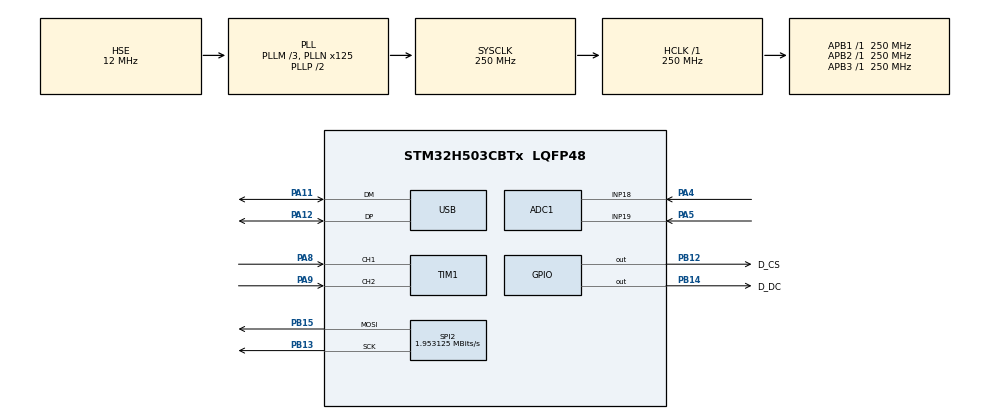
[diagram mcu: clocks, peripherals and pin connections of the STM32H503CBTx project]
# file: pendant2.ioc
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ADC1.Channel-0\#ChannelRegularConversion=ADC_CHANNEL_18
ADC1.Channel-1\#ChannelRegularConversion=ADC_CHANNEL_19
ADC1.ContinuousConvMode=ENABLE
ADC1.DMAContinuousRequests=ENABLE
ADC1.EOCSelection=ADC_EOC_SEQ_CONV
ADC1.MonitoredBy-0\#ChannelRegularConversion=__NULL
ADC1.MonitoredBy-1\#ChannelRegularConversion=__NULL
ADC1.NbrOfConversion=2
ADC1.NbrOfConversionFlag=1
ADC1.OffsetNumber-0\#ChannelRegularConversion=ADC_OFFSET_NONE
ADC1.OffsetNumber-1\#ChannelRegularConversion=ADC_OFFSET_NONE
ADC1.Rank-0\#ChannelRegularConversion=1
ADC1.Rank-1\#ChannelRegularConversion=2
ADC1.SamplingMode=ADC_SAMPLING_MODE_NORMAL
ADC1.SamplingTime-0\#ChannelRegularConversion=ADC_SAMPLETIME_47CYCLES_5
ADC1.SamplingTime-1\#ChannelRegularConversion=ADC_SAMPLETIME_47CYCLES_5
ADC1.master=1
BOOTPATH.BootPathName=LEGACY
BOOTPATH.UserSelectedBootPath=LEGACY
GPDMA1.CIRCULARMODE_GPDMACH2=ENABLE
GPDMA1.DESTDATAWIDTH_GPDMACH2=DMA_DEST_DATAWIDTH_WORD
GPDMA1.DESTINC_GPDMACH2=DMA_DINC_INCREMENTED
GPDMA1.DIRECTION_GPDMACH0=DMA_MEMORY_TO_PERIPH
GPDMA1.IPHANDLE_GPDMACH0-SIMPLEREQUEST_GPDMACH0=__NULL
GPDMA1.IPHANDLE_GPDMACH2-SIMPLEREQUEST_GPDMACH2=__NULL
GPDMA1.REQUEST_GPDMACH0=GPDMA1_REQUEST_SPI2_TX
GPDMA1.REQUEST_GPDMACH2=GPDMA1_REQUEST_ADC1
GPDMA1.SRCBURSTLENGTH_GPDMACH0=64
GPDMA1.SRCDATAWIDTH_GPDMACH2=DMA_SRC_DATAWIDTH_WORD
GPDMA1.SRCINC_GPDMACH0=DMA_SINC_INCREMENTED
Mcu.Family=STM32H5
Mcu.Name=STM32H503CBTx
Mcu.Package=LQFP48
NVIC.GPDMA1_Channel0_IRQn=true\:0\:0\:false\:false\:true\:false\:true\:true
NVIC.GPDMA1_Channel2_IRQn=true\:0\:0\:false\:false\:true\:false\:true\:true
NVIC.PriorityGroup=NVIC_PRIORITYGROUP_4
NVIC.SPI2_IRQn=true\:0\:0\:false\:false\:true\:true\:true\:true
NVIC.USB_DRD_FS_IRQn=true\:0\:0\:false\:false\:true\:true\:true\:true
PA11.Mode=Device
PA11.Signal=USB_DM
PA12.Mode=Device
PA12.Signal=USB_DP
PA3.Signal=ADCx_INP15
PA4.Signal=ADCx_INP18
PA5.Signal=ADCx_INP19
PA8.Signal=S_TIM1_CH1
PA9.Signal=S_TIM1_CH2
PB12.GPIO_Label=D_CS
PB12.Signal=GPIO_Output
PB13.Mode=TX_Only_Simplex_Unidirect_Master
PB13.Signal=SPI2_SCK
PB14.GPIO_Label=D_DC
PB14.Signal=GPIO_Output
PB15.Mode=TX_Only_Simplex_Unidirect_Master
PB15.Signal=SPI2_MOSI
PH0-OSC_IN(PH0).Mode=HSE-External-Oscillator
PH0-OSC_IN(PH0).Signal=RCC_OSC_IN
PH1-OSC_OUT(PH1).Mode=HSE-External-Oscillator
PH1-OSC_OUT(PH1).Signal=RCC_OSC_OUT
ProjectManager.HeapSize=0x300
ProjectManager.StackSize=0x500
ProjectManager.TargetToolchain=Makefile
RCC.ADCCLockSelection=RCC_ADCDACCLKSOURCE_CSI
RCC.ADCFreq_Value=4000000
RCC.AHBFreq_Value=250000000
RCC.APB1Freq_Value=250000000
RCC.APB1TimFreq_Value=250000000
RCC.APB2Freq_Value=250000000
RCC.APB2TimFreq_Value=250000000
RCC.APB3Freq_Value=250000000
RCC.CSI_VALUE=4000000
RCC.CortexFreq_Value=250000000
RCC.EPOD_VALUE=12000000
RCC.EnbaleCSS=true
RCC.HCLKFreq_Value=250000000
RCC.HSE_VALUE=12000000
RCC.HSI48_VALUE=48000000
RCC.HSI_VALUE=64000000
RCC.LSE_VALUE=32768
RCC.LSIRC_VALUE=32000
RCC.PLL2FRACN=0
RCC.PLL2Source=RCC_PLL2_SOURCE_HSE
RCC.PLLFRACN=0
RCC.PLLM=3
RCC.PLLN=125
RCC.PLLSourceVirtual=RCC_PLL1_SOURCE_HSE
RCC.SYSCLKFreq_VALUE=250000000
RCC.SYSCLKSource=RCC_SYSCLKSOURCE_PLLCLK
RCC.USBFreq_Value=48000000
RCC.VCOOutputFreq_Value=500000000
SH.ADCx_INP15.0=ADC1_INP15
SH.ADCx_INP18.0=ADC1_INP18,IN18-Single-Ended
SH.ADCx_INP19.0=ADC1_INP19,IN19-Single-Ended
SH.S_TIM1_CH1.0=TIM1_CH1,Encoder_Interface
SH.S_TIM1_CH2.0=TIM1_CH2,Encoder_Interface
SPI2.BaudRatePrescaler=SPI_BAUDRATEPRESCALER_128
SPI2.CLKPolarity=SPI_POLARITY_LOW
SPI2.CalculateBaudRate=1.953125 MBits/s
SPI2.DataSize=SPI_DATASIZE_8BIT
SPI2.Direction=SPI_DIRECTION_2LINES_TXONLY
SPI2.Mode=SPI_MODE_MASTER
SPI2.VirtualType=VM_MASTER
TIM1.EncoderMode=TIM_ENCODERMODE_X1_TI1
USB.VirtualMode=Device_Only
VP_ADC1_TempSens_Input.Mode=IN-TempSens
VP_ADC1_Vref_Input.Mode=IN-Vrefint
VP_BOOTPATH_VS_BOOTPATH.Mode=BP_Activate
VP_CORTEX_M33_NS_VS_Hclk.Mode=Hclk_Mode
VP_CRC_VS_CRC.Mode=CRC_Activate
VP_FLASH_SIG_Activate_FlashIP.Mode=Activate_FlashIP
VP_GPDMA1_VS_GPDMACH0.Mode=SIMPLEREQUEST_GPDMACH0
VP_GPDMA1_VS_GPDMACH2.Mode=SIMPLEREQUEST_GPDMACH2
VP_ICACHE_VS_ICACHE.Mode=DirectMappedCache
VP_MEMORYMAP_VS_MEMORYMAP.Mode=CurAppReg
VP_PWR_VS_DBSignals.Mode=DisableDeadBatterySignals
VP_PWR_VS_LPOM.Mode=PowerOptimisation
VP_PWR_VS_SECSignals.Mode=Security/Privilege
board=custom

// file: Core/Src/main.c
/* USER CODE BEGIN Header */
/**
  ******************************************************************************
  * @file           : main.c
  * @brief          : Main program body
  ******************************************************************************
  * @attention
  *
  * Copyright (c) 2024 STMicroelectronics.
  * All rights reserved.
  *
  * This software is licensed under terms that can be found in the LICENSE file
  * in the root directory of this software component.
  * If no LICENSE file comes with this software, it is provided AS-IS.
  *
  ******************************************************************************
  */
/* USER CODE END Header */
#include "main.h"

/* USER CODE BEGIN Includes */
#include "usbd_core.h"
#include "usbd_device.h"
#include "platform.h"
/* USER CODE END Includes */

/* USER CODE BEGIN PTD */
USBD_HandleTypeDef hUsbDeviceFS = {0};
extern USBD_DescriptorsTypeDef usbd_class_descriptors;
/* USER CODE END PTD */

ADC_HandleTypeDef hadc1;
DMA_NodeTypeDef Node_GPDMA1_Channel2;
DMA_QListTypeDef List_GPDMA1_Channel2;
DMA_HandleTypeDef handle_GPDMA1_Channel2;

CRC_HandleTypeDef hcrc;

SPI_HandleTypeDef hspi2;
DMA_HandleTypeDef handle_GPDMA1_Channel0;

TIM_HandleTypeDef htim1;

PCD_HandleTypeDef hpcd_USB_DRD_FS;

void SystemClock_Config(void);
static void MX_GPIO_Init(void);
static void MX_GPDMA1_Init(void);
static void MX_CRC_Init(void);
static void MX_FLASH_Init(void);
static void MX_ICACHE_Init(void);
static void MX_USB_PCD_Init(void);
static void MX_ADC1_Init(void);
static void MX_SPI2_Init(void);
static void MX_TIM1_Init(void);

int main(void)
{

  /* MCU Configuration--------------------------------------------------------*/

  /* Reset of all peripherals, Initializes the Flash interface and the Systick. */
  HAL_Init();

  /* Configure the system clock */
  SystemClock_Config();

  /* USER CODE BEGIN SysInit */
  usdb_desc_init();
  /* USER CODE END SysInit */

  /* Initialize all configured peripherals */
  MX_GPIO_Init();
  MX_GPDMA1_Init();
  MX_CRC_Init();
  MX_FLASH_Init();
  MX_ICACHE_Init();
  MX_USB_PCD_Init();
  MX_ADC1_Init();
  MX_SPI2_Init();
  MX_TIM1_Init();
  /* USER CODE BEGIN 2 */
  init();
  /* USER CODE END 2 */

  /* Infinite loop */
  /* USER CODE BEGIN WHILE */
  while (1)
  {
    loop();
    /* USER CODE END WHILE */

  }
}

void SystemClock_Config(void)
{
  RCC_OscInitTypeDef RCC_OscInitStruct = {0};
  RCC_ClkInitTypeDef RCC_ClkInitStruct = {0};

  /** Configure the main internal regulator output voltage
  */
  __HAL_PWR_VOLTAGESCALING_CONFIG(PWR_REGULATOR_VOLTAGE_SCALE0);

  while(!__HAL_PWR_GET_FLAG(PWR_FLAG_VOSRDY)) {}

  /** Initializes the RCC Oscillators according to the specified parameters
  * in the RCC_OscInitTypeDef structure.
  */
  RCC_OscInitStruct.OscillatorType = RCC_OSCILLATORTYPE_HSI48|RCC_OSCILLATORTYPE_HSE
                              |RCC_OSCILLATORTYPE_CSI;
  RCC_OscInitStruct.HSEState = RCC_HSE_ON;
  RCC_OscInitStruct.HSI48State = RCC_HSI48_ON;
  RCC_OscInitStruct.CSIState = RCC_CSI_ON;
  RCC_OscInitStruct.CSICalibrationValue = RCC_CSICALIBRATION_DEFAULT;
  RCC_OscInitStruct.PLL.PLLState = RCC_PLL_ON;
  RCC_OscInitStruct.PLL.PLLSource = RCC_PLL1_SOURCE_HSE;
  RCC_OscInitStruct.PLL.PLLM = 3;
  RCC_OscInitStruct.PLL.PLLN = 125;
  RCC_OscInitStruct.PLL.PLLP = 2;
  RCC_OscInitStruct.PLL.PLLQ = 2;
  RCC_OscInitStruct.PLL.PLLR = 2;
  RCC_OscInitStruct.PLL.PLLRGE = RCC_PLL1_VCIRANGE_2;
  RCC_OscInitStruct.PLL.PLLVCOSEL = RCC_PLL1_VCORANGE_WIDE;
  RCC_OscInitStruct.PLL.PLLFRACN = 0;
  if (HAL_RCC_OscConfig(&RCC_OscInitStruct) != HAL_OK)
  {
    Error_Handler();
  }

  /** Initializes the CPU, AHB and APB buses clocks
  */
  RCC_ClkInitStruct.ClockType = RCC_CLOCKTYPE_HCLK|RCC_CLOCKTYPE_SYSCLK
                              |RCC_CLOCKTYPE_PCLK1|RCC_CLOCKTYPE_PCLK2
                              |RCC_CLOCKTYPE_PCLK3;
  RCC_ClkInitStruct.SYSCLKSource = RCC_SYSCLKSOURCE_PLLCLK;
  RCC_ClkInitStruct.AHBCLKDivider = RCC_SYSCLK_DIV1;
  RCC_ClkInitStruct.APB1CLKDivider = RCC_HCLK_DIV1;
  RCC_ClkInitStruct.APB2CLKDivider = RCC_HCLK_DIV1;
  RCC_ClkInitStruct.APB3CLKDivider = RCC_HCLK_DIV1;

  if (HAL_RCC_ClockConfig(&RCC_ClkInitStruct, FLASH_LATENCY_5) != HAL_OK)
  {
    Error_Handler();
  }

  /** Enables the Clock Security System
  */
  HAL_RCC_EnableCSS();

  /** Configure the programming delay
  */
  __HAL_FLASH_SET_PROGRAM_DELAY(FLASH_PROGRAMMING_DELAY_2);
}

static void MX_ADC1_Init(void)
{

  ADC_ChannelConfTypeDef sConfig = {0};

  /** Common config
  */
  hadc1.Instance = ADC1;
  hadc1.Init.ClockPrescaler = ADC_CLOCK_ASYNC_DIV1;
  hadc1.Init.Resolution = ADC_RESOLUTION_12B;
  hadc1.Init.DataAlign = ADC_DATAALIGN_RIGHT;
  hadc1.Init.ScanConvMode = ADC_SCAN_ENABLE;
  hadc1.Init.EOCSelection = ADC_EOC_SEQ_CONV;
  hadc1.Init.LowPowerAutoWait = DISABLE;
  hadc1.Init.ContinuousConvMode = ENABLE;
  hadc1.Init.NbrOfConversion = 2;
  hadc1.Init.DiscontinuousConvMode = DISABLE;
  hadc1.Init.ExternalTrigConv = ADC_SOFTWARE_START;
  hadc1.Init.ExternalTrigConvEdge = ADC_EXTERNALTRIGCONVEDGE_NONE;
  hadc1.Init.DMAContinuousRequests = ENABLE;
  hadc1.Init.SamplingMode = ADC_SAMPLING_MODE_NORMAL;
  hadc1.Init.Overrun = ADC_OVR_DATA_PRESERVED;
  hadc1.Init.OversamplingMode = DISABLE;
  if (HAL_ADC_Init(&hadc1) != HAL_OK)
  {
    Error_Handler();
  }

  /** Configure Regular Channel
  */
  sConfig.Channel = ADC_CHANNEL_18;
  sConfig.Rank = ADC_REGULAR_RANK_1;
  sConfig.SamplingTime = ADC_SAMPLETIME_47CYCLES_5;
  sConfig.SingleDiff = ADC_SINGLE_ENDED;
  sConfig.OffsetNumber = ADC_OFFSET_NONE;
  sConfig.Offset = 0;
  if (HAL_ADC_ConfigChannel(&hadc1, &sConfig) != HAL_OK)
  {
    Error_Handler();
  }

  /** Configure Regular Channel
  */
  sConfig.Channel = ADC_CHANNEL_19;
  sConfig.Rank = ADC_REGULAR_RANK_2;
  if (HAL_ADC_ConfigChannel(&hadc1, &sConfig) != HAL_OK)
  {
    Error_Handler();
  }
  /* USER CODE BEGIN ADC1_Init 2 */
HAL_ADCEx_Calibration_Start(&hadc1, ADC_SINGLE_ENDED);
  /* USER CODE END ADC1_Init 2 */

}

static void MX_CRC_Init(void)
{

  hcrc.Instance = CRC;
  hcrc.Init.DefaultPolynomialUse = DEFAULT_POLYNOMIAL_ENABLE;
  hcrc.Init.DefaultInitValueUse = DEFAULT_INIT_VALUE_ENABLE;
  hcrc.Init.InputDataInversionMode = CRC_INPUTDATA_INVERSION_NONE;
  hcrc.Init.OutputDataInversionMode = CRC_OUTPUTDATA_INVERSION_DISABLE;
  hcrc.InputDataFormat = CRC_INPUTDATA_FORMAT_BYTES;
  if (HAL_CRC_Init(&hcrc) != HAL_OK)
  {
    Error_Handler();
  }

}

static void MX_FLASH_Init(void)
{

  if (HAL_FLASH_Unlock() != HAL_OK)
  {
    Error_Handler();
  }
  if (HAL_FLASH_Lock() != HAL_OK)
  {
    Error_Handler();
  }

}

static void MX_GPDMA1_Init(void)
{

  /* Peripheral clock enable */
  __HAL_RCC_GPDMA1_CLK_ENABLE();

  /* GPDMA1 interrupt Init */
    HAL_NVIC_SetPriority(GPDMA1_Channel0_IRQn, 0, 0);
    HAL_NVIC_EnableIRQ(GPDMA1_Channel0_IRQn);
    HAL_NVIC_SetPriority(GPDMA1_Channel2_IRQn, 0, 0);
    HAL_NVIC_EnableIRQ(GPDMA1_Channel2_IRQn);

}

static void MX_ICACHE_Init(void)
{

  /** Enable instruction cache in 1-way (direct mapped cache)
  */
  if (HAL_ICACHE_ConfigAssociativityMode(ICACHE_1WAY) != HAL_OK)
  {
    Error_Handler();
  }
  if (HAL_ICACHE_Enable() != HAL_OK)
  {
    Error_Handler();
  }

}

static void MX_SPI2_Init(void)
{

  /* SPI2 parameter configuration*/
  hspi2.Instance = SPI2;
  hspi2.Init.Mode = SPI_MODE_MASTER;
  hspi2.Init.Direction = SPI_DIRECTION_2LINES_TXONLY;
  hspi2.Init.DataSize = SPI_DATASIZE_8BIT;
  hspi2.Init.CLKPolarity = SPI_POLARITY_LOW;
  hspi2.Init.CLKPhase = SPI_PHASE_1EDGE;
  hspi2.Init.NSS = SPI_NSS_SOFT;
  hspi2.Init.BaudRatePrescaler = SPI_BAUDRATEPRESCALER_128;
  hspi2.Init.FirstBit = SPI_FIRSTBIT_MSB;
  hspi2.Init.TIMode = SPI_TIMODE_DISABLE;
  hspi2.Init.CRCCalculation = SPI_CRCCALCULATION_DISABLE;
  hspi2.Init.CRCPolynomial = 0x7;
  hspi2.Init.NSSPMode = SPI_NSS_PULSE_ENABLE;
  hspi2.Init.NSSPolarity = SPI_NSS_POLARITY_LOW;
  hspi2.Init.FifoThreshold = SPI_FIFO_THRESHOLD_01DATA;
  hspi2.Init.MasterSSIdleness = SPI_MASTER_SS_IDLENESS_00CYCLE;
  hspi2.Init.MasterInterDataIdleness = SPI_MASTER_INTERDATA_IDLENESS_00CYCLE;
  hspi2.Init.MasterReceiverAutoSusp = SPI_MASTER_RX_AUTOSUSP_DISABLE;
  hspi2.Init.MasterKeepIOState = SPI_MASTER_KEEP_IO_STATE_DISABLE;
  hspi2.Init.IOSwap = SPI_IO_SWAP_DISABLE;
  hspi2.Init.ReadyMasterManagement = SPI_RDY_MASTER_MANAGEMENT_INTERNALLY;
  hspi2.Init.ReadyPolarity = SPI_RDY_POLARITY_HIGH;
  if (HAL_SPI_Init(&hspi2) != HAL_OK)
  {
    Error_Handler();
  }

}

static void MX_TIM1_Init(void)
{

  TIM_Encoder_InitTypeDef sConfig = {0};
  TIM_MasterConfigTypeDef sMasterConfig = {0};

  htim1.Instance = TIM1;
  htim1.Init.Prescaler = 0;
  htim1.Init.CounterMode = TIM_COUNTERMODE_UP;
  htim1.Init.Period = 65535;
  htim1.Init.ClockDivision = TIM_CLOCKDIVISION_DIV1;
  htim1.Init.RepetitionCounter = 0;
  htim1.Init.AutoReloadPreload = TIM_AUTORELOAD_PRELOAD_DISABLE;
  sConfig.EncoderMode = TIM_ENCODERMODE_X1_TI1;
  sConfig.IC1Polarity = TIM_ICPOLARITY_RISING;
  sConfig.IC1Selection = TIM_ICSELECTION_DIRECTTI;
  sConfig.IC1Prescaler = TIM_ICPSC_DIV1;
  sConfig.IC1Filter = 0;
  sConfig.IC2Polarity = TIM_ICPOLARITY_RISING;
  sConfig.IC2Selection = TIM_ICSELECTION_DIRECTTI;
  sConfig.IC2Prescaler = TIM_ICPSC_DIV1;
  sConfig.IC2Filter = 0;
  if (HAL_TIM_Encoder_Init(&htim1, &sConfig) != HAL_OK)
  {
    Error_Handler();
  }
  sMasterConfig.MasterOutputTrigger = TIM_TRGO_RESET;
  sMasterConfig.MasterOutputTrigger2 = TIM_TRGO2_RESET;
  sMasterConfig.MasterSlaveMode = TIM_MASTERSLAVEMODE_DISABLE;
  if (HAL_TIMEx_MasterConfigSynchronization(&htim1, &sMasterConfig) != HAL_OK)
  {
    Error_Handler();
  }

}

static void MX_USB_PCD_Init(void)
{

  /* USER CODE BEGIN USB_Init 0 */
  hpcd_USB_DRD_FS.pData = &hUsbDeviceFS;
  /* USER CODE END USB_Init 0 */

  hpcd_USB_DRD_FS.Instance = USB_DRD_FS;
  hpcd_USB_DRD_FS.Init.dev_endpoints = 8;
  hpcd_USB_DRD_FS.Init.speed = USBD_FS_SPEED;
  hpcd_USB_DRD_FS.Init.phy_itface = PCD_PHY_EMBEDDED;
  hpcd_USB_DRD_FS.Init.Sof_enable = DISABLE;
  hpcd_USB_DRD_FS.Init.low_power_enable = DISABLE;
  hpcd_USB_DRD_FS.Init.lpm_enable = DISABLE;
  hpcd_USB_DRD_FS.Init.battery_charging_enable = DISABLE;
  hpcd_USB_DRD_FS.Init.vbus_sensing_enable = DISABLE;
  hpcd_USB_DRD_FS.Init.bulk_doublebuffer_enable = DISABLE;
  hpcd_USB_DRD_FS.Init.iso_singlebuffer_enable = DISABLE;
  if (HAL_PCD_Init(&hpcd_USB_DRD_FS) != HAL_OK)
  {
    Error_Handler();
  }
  /* USER CODE BEGIN USB_Init 2 */
	if(USBD_Init(&hUsbDeviceFS, &usbd_class_descriptors, 0) != USBD_OK) Error_Handler();
	if(USBD_RegisterClass(&hUsbDeviceFS, &usbd_class_device) != USBD_OK) Error_Handler();
	if(USBD_Start(&hUsbDeviceFS) != USBD_OK) Error_Handler();
  /* USER CODE END USB_Init 2 */

}

static void MX_GPIO_Init(void)
{
  GPIO_InitTypeDef GPIO_InitStruct = {0};

  /* GPIO Ports Clock Enable */
  __HAL_RCC_GPIOH_CLK_ENABLE();
  __HAL_RCC_GPIOA_CLK_ENABLE();
  __HAL_RCC_GPIOB_CLK_ENABLE();

  /*Configure GPIO pin Output Level */
  HAL_GPIO_WritePin(GPIOB, D_CS_Pin|D_DC_Pin, GPIO_PIN_RESET);

  /*Configure GPIO pins : D_CS_Pin D_DC_Pin */
  GPIO_InitStruct.Pin = D_CS_Pin|D_DC_Pin;
  GPIO_InitStruct.Mode = GPIO_MODE_OUTPUT_PP;
  GPIO_InitStruct.Pull = GPIO_NOPULL;
  GPIO_InitStruct.Speed = GPIO_SPEED_FREQ_LOW;
  HAL_GPIO_Init(GPIOB, &GPIO_InitStruct);

}

void Error_Handler(void)
{
  __disable_irq();
  while (1)
  {
  }
}
